VERSION "created by canmatrix"

NS_ :

BS_:

BU_: air_ctrl bms_core brakelight_bspd throttle dashboard

BO_ 0 Panic: 8 air_ctrl
 SG_ Panic : 7|2@0+ (1,1) [0|1] "" air_ctrl,bms_core,throttle,brakelight_bspd

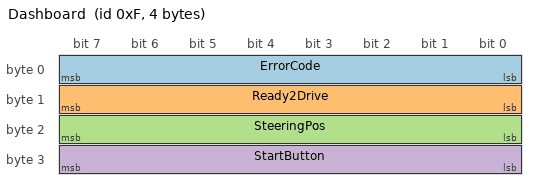
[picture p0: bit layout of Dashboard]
BO_ 15 Dashboard: 4 dashboard
 SG_ ErrorCode : 7|8@0+ (1,0) [0|1] "" Vector_XXX
 SG_ Ready2Drive : 15|8@0+ (1,0) [0|1] "" Vector_XXX
 SG_ SteeringPos : 23|8@0+ (1,0) [0|1] "" Vector_XXX
 SG_ StartButton : 31|8@0+ (1,0) [0|1] "" Vector_XXX
